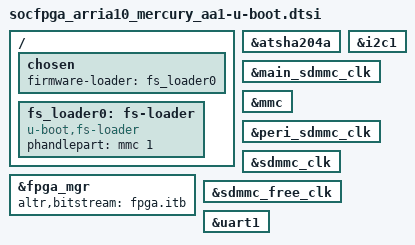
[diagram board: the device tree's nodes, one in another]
// SPDX-License-Identifier: GPL-2.0
/*
 * Copyright 2022 Google LLC
 */
#include "socfpga_arria10-u-boot.dtsi"

/ {
	chosen {
		firmware-loader = <&fs_loader0>;
	};

	fs_loader0: fs-loader {
		u-boot,dm-all;
		compatible = "u-boot,fs-loader";
		phandlepart = <&mmc 1>;
	};
};

&atsha204a {
	u-boot,dm-all;
};

&fpga_mgr {
	u-boot,dm-all;
	altr,bitstream = "fpga.itb";
};

&i2c1 {
	u-boot,dm-all;
};

&main_sdmmc_clk {
	u-boot,dm-all;
};

&mmc {
	u-boot,dm-all;
};

&peri_sdmmc_clk {
	u-boot,dm-all;
};

&sdmmc_clk {
	u-boot,dm-all;
};

&sdmmc_free_clk {
	u-boot,dm-all;
};

&uart1 {
	u-boot,dm-all;
};
